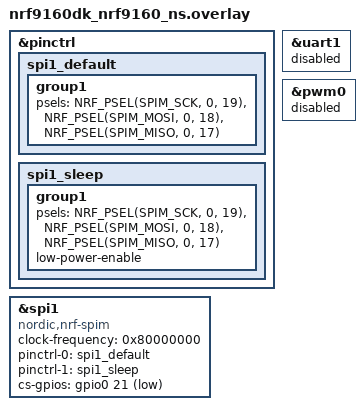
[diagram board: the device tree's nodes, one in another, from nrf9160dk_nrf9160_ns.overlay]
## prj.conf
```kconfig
#
# Copyright (c) 2020 Nordic Semiconductor ASA
#
# SPDX-License-Identifier: LicenseRef-BSD-5-Clause-Nordic
#
# CONFIG_BOARD_ENABLE_CPUNET=n
CONFIG_SPI=y
CONFIG_MAIN_STACK_SIZE=4096
# CONFIG_SPI_0=y
# UART, SPIM, and I2C are shared peripherals on nrf9160
# therefore we choose SPI3
#CONFIG_SPI_NRFX=y

CONFIG_DEBUG_OPTIMIZATIONS=y
```

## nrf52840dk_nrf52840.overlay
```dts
&spi1 {
	compatible = "nordic,nrf-spim";
	status = "okay";
	sck-pin = <4>;
	mosi-pin = <6>;
	miso-pin = <11>;
	cs-gpios = <&gpio0 13 0>;
};
```

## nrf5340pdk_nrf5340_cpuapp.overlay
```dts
&spi1 {
	compatible = "nordic,nrf-spim";
	status = "okay";
	sck-pin = <10>;
	mosi-pin = <11>;
	miso-pin = <12>;
};
```

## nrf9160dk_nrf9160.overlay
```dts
nrf9160dk_nrf9160ns.overlay
```

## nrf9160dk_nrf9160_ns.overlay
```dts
&pinctrl {
	spi1_default: spi1_default {
		group1 {
			psels = <NRF_PSEL(SPIM_SCK, 0, 19)>,
					<NRF_PSEL(SPIM_MOSI, 0, 18)>,
					<NRF_PSEL(SPIM_MISO, 0, 17)>;
		};
	};

	spi1_sleep: spi1_sleep {
		group1 {
			psels = <NRF_PSEL(SPIM_SCK, 0, 19)>,
					<NRF_PSEL(SPIM_MOSI, 0, 18)>,
					<NRF_PSEL(SPIM_MISO, 0, 17)>;
			low-power-enable;
		};
	};
};

&spi1 {
	compatible = "nordic,nrf-spim";
	clock-frequency = <0x80000000>;
	status = "okay";
	//sck-pin = <19>;
	//mosi-pin = <18>;
	//miso-pin = <17>;
	pinctrl-0 = <&spi1_default>;
	pinctrl-1 = <&spi1_sleep>;
	pinctrl-names = "default", "sleep";
	cs-gpios = <&gpio0 21 GPIO_ACTIVE_LOW>;
};

&uart1 {
	status = "disabled";
};
&pwm0 { 
	status = "disabled";
};
```

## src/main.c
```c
/*
* Copyright (c) 2012-2014 Wind River Systems, Inc.
*
* SPDX-License-Identifier: Apache-2.0
*/

#include <zephyr.h>
#include <sys/printk.h>
#include <drivers/spi.h>

#define DT_DRV_COMPAT nordic_nrf_spim

struct spi_cs_control spi_cs = {
	.gpio_pin = DT_GPIO_PIN(DT_DRV_INST(0), cs_gpios),
	.gpio_dt_flags = GPIO_ACTIVE_LOW,
	.delay = 0,
};

static struct spi_config spi_cfg = {
	.operation = SPI_WORD_SET(8) | SPI_TRANSFER_MSB |
		     SPI_MODE_CPOL | SPI_MODE_CPHA,
	.frequency = 4000000,
	.slave = 0,
	.cs = &spi_cs,
};

const struct device * spi_dev;

static void spi_init(void)
{
	spi_cs.gpio_dev = device_get_binding(DT_GPIO_LABEL(DT_DRV_INST(0), cs_gpios));

	if (spi_cs.gpio_dev == NULL) {
	    printk("Could not get gpio device\n");
	} else {
		printk("GPIO device: %s\n", DT_GPIO_LABEL(DT_DRV_INST(0), cs_gpios));
	}

	spi_dev = device_get_binding(DT_LABEL(DT_DRV_INST(0)));

	if (spi_dev == NULL) {
		printk("Could not get %s device\n", DT_LABEL(DT_DRV_INST(0)));
		return;
	} else {
		printk("SPI Device: %s\n", DT_LABEL(DT_DRV_INST(0)));
		/*printk("SPI CSN %d, MISO %d, MOSI %d, CLK %d\n",
	       DT_GPIO_PIN(DT_DRV_INST(0), cs_gpios),
	       DT_PROP(DT_DRV_INST(0), miso_pin),
	       DT_PROP(DT_DRV_INST(0), mosi_pin),
	       DT_PROP(DT_DRV_INST(0), sck_pin));	*/	
	}
}

void spi_test_send(void)
{
	int err;
	static uint8_t tx_buffer[32];
	static uint8_t rx_buffer[32];

	const struct spi_buf tx_buf = {
		.buf = tx_buffer,
		.len = sizeof(tx_buffer)
	};
	const struct spi_buf_set tx = {
		.buffers = &tx_buf,
		.count = 1
	};

	struct spi_buf rx_buf = {
		.buf = rx_buffer,
		.len = sizeof(rx_buffer),
	};
	const struct spi_buf_set rx = {
		.buffers = &rx_buf,
		.count = 1
	};

	err = spi_transceive(spi_dev, &spi_cfg, &tx, &rx);
	if (err) {
		printk("SPI error: %d\n", err);
	} else {
		/* Connect MISO to MOSI for loopback */
		printk("TX sent: %x\n", tx_buffer[0]);
		printk("RX recv: %x\n", rx_buffer[0]);
		tx_buffer[0]++;
	}
}

void main(void)
{
	printk("SPIM Example\n");	
	spi_init();	
	while (1) {
		spi_test_send();
		k_sleep(K_MSEC(1000));
	}
}
```
